AUTOSAR XML (schema 4-0-3)
standard types defined: Boolean, UInt16
package /AUTOSAR_Platform/DataConstrs
  range DC_Boolean: raw 0..1
  range DC_UInt16: raw 0..65535
package /PATAC/MSM/ComponentTypes
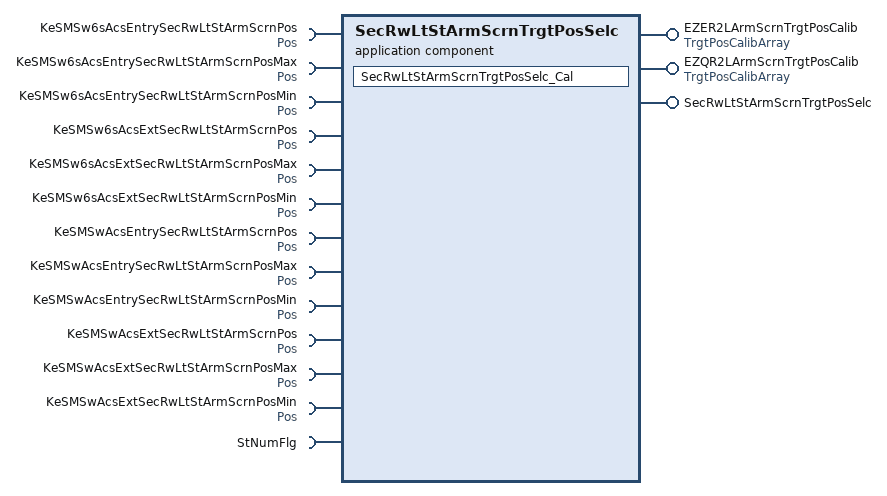
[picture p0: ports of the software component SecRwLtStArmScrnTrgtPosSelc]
  application sw component type SecRwLtStArmScrnTrgtPosSelc
    provide port EZER2LArmScrnTrgtPosCalib: nonqueued-sender-com-spec{data-element=TrgtPosArray, init-value=[4095, 4095, 4095]}, provided-interface=TrgtPosCalibArray
    provide port EZQR2LArmScrnTrgtPosCalib: nonqueued-sender-com-spec{data-element=TrgtPosArray, init-value=[4095, 4095, 4095]}, provided-interface=TrgtPosCalibArray
    provide port SecRwLtStArmScrnTrgtPosSelc: server-com-spec{operation=Cal, queue-length=1}, provided-interface=SecRwLtStArmScrnTrgtPosSelc
    13 x require port:
      KeSMSw6sAcsEntrySecRwLtStArmScrnPos: parameter-require-com-spec{init-value=0, parameter=Val}, required-interface=Pos
      KeSMSw6sAcsEntrySecRwLtStArmScrnPosMax: parameter-require-com-spec{init-value=0, parameter=Val}, required-interface=Pos
      KeSMSw6sAcsEntrySecRwLtStArmScrnPosMin: parameter-require-com-spec{init-value=0, parameter=Val}, required-interface=Pos
      KeSMSw6sAcsExtSecRwLtStArmScrnPos: parameter-require-com-spec{init-value=30, parameter=Val}, required-interface=Pos
      KeSMSw6sAcsExtSecRwLtStArmScrnPosMax: parameter-require-com-spec{init-value=40, parameter=Val}, required-interface=Pos
      KeSMSw6sAcsExtSecRwLtStArmScrnPosMin: parameter-require-com-spec{init-value=20, parameter=Val}, required-interface=Pos
      KeSMSwAcsEntrySecRwLtStArmScrnPos: parameter-require-com-spec{init-value=0, parameter=Val}, required-interface=Pos
      KeSMSwAcsEntrySecRwLtStArmScrnPosMax: parameter-require-com-spec{init-value=0, parameter=Val}, required-interface=Pos
      KeSMSwAcsEntrySecRwLtStArmScrnPosMin: parameter-require-com-spec{init-value=0, parameter=Val}, required-interface=Pos
      KeSMSwAcsExtSecRwLtStArmScrnPos: parameter-require-com-spec{init-value=30, parameter=Val}, required-interface=Pos
      KeSMSwAcsExtSecRwLtStArmScrnPosMax: parameter-require-com-spec{init-value=40, parameter=Val}, required-interface=Pos
      KeSMSwAcsExtSecRwLtStArmScrnPosMin: parameter-require-com-spec{init-value=20, parameter=Val}, required-interface=Pos
      StNumFlg: required-interface=StNumFlg
        required-com-specs:
          data-element=Is4s, filter=data-filter-type=ALWAYS, init-value=0
          data-element=Is6s, filter=data-filter-type=ALWAYS, init-value=0
          data-element=Is6s7s, filter=data-filter-type=ALWAYS, init-value=0
          data-element=Is7s, filter=data-filter-type=ALWAYS, init-value=0
    behavior SecRwLtStArmScrnTrgtPosSelc_InternalBehavior
      operation invoked event OIT_SecRwLtStArmScrnTrgtPosSelc_Cal_SecRwLtStArmScrnTrgtPosSelc_Cal: start-on-event=SecRwLtStArmScrnTrgtPosSelc_Cal, operation=SecRwLtStArmScrnTrgtPosSelc.Cal
      runnable SecRwLtStArmScrnTrgtPosSelc_Cal
        data-receive-point-by-arguments:
          4 x access:
            REC_StNumFlg_Is4s: accessed-variable=StNumFlg.Is4s
            REC_StNumFlg_Is6s: accessed-variable=StNumFlg.Is6s
            REC_StNumFlg_Is6s7s: accessed-variable=StNumFlg.Is6s7s
            REC_StNumFlg_Is7s: accessed-variable=StNumFlg.Is7s
        data-send-points:
          access SEND_EZER2LArmScrnTrgtPosCalib_TrgtPosArray: accessed-variable=EZER2LArmScrnTrgtPosCalib.TrgtPosArray
          access SEND_EZQR2LArmScrnTrgtPosCalib_TrgtPosArray: accessed-variable=EZQR2LArmScrnTrgtPosCalib.TrgtPosArray
        12 x parameter access:
          PA_KeSMSw6sAcsEntrySecRwLtStArmScrnPos_Val: accessed-parameter=KeSMSw6sAcsEntrySecRwLtStArmScrnPos.Val
          PA_KeSMSw6sAcsEntrySecRwLtStArmScrnPosMax_Val: accessed-parameter=KeSMSw6sAcsEntrySecRwLtStArmScrnPosMax.Val
          PA_KeSMSw6sAcsEntrySecRwLtStArmScrnPosMin_Val: accessed-parameter=KeSMSw6sAcsEntrySecRwLtStArmScrnPosMin.Val
          PA_KeSMSw6sAcsExtSecRwLtStArmScrnPos_Val: accessed-parameter=KeSMSw6sAcsExtSecRwLtStArmScrnPos.Val
          PA_KeSMSw6sAcsExtSecRwLtStArmScrnPosMax_Val: accessed-parameter=KeSMSw6sAcsExtSecRwLtStArmScrnPosMax.Val
          PA_KeSMSw6sAcsExtSecRwLtStArmScrnPosMin_Val: accessed-parameter=KeSMSw6sAcsExtSecRwLtStArmScrnPosMin.Val
          PA_KeSMSwAcsEntrySecRwLtStArmScrnPos_Val: accessed-parameter=KeSMSwAcsEntrySecRwLtStArmScrnPos.Val
          PA_KeSMSwAcsEntrySecRwLtStArmScrnPosMax_Val: accessed-parameter=KeSMSwAcsEntrySecRwLtStArmScrnPosMax.Val
          PA_KeSMSwAcsEntrySecRwLtStArmScrnPosMin_Val: accessed-parameter=KeSMSwAcsEntrySecRwLtStArmScrnPosMin.Val
          PA_KeSMSwAcsExtSecRwLtStArmScrnPos_Val: accessed-parameter=KeSMSwAcsExtSecRwLtStArmScrnPos.Val
          PA_KeSMSwAcsExtSecRwLtStArmScrnPosMax_Val: accessed-parameter=KeSMSwAcsExtSecRwLtStArmScrnPosMax.Val
          PA_KeSMSwAcsExtSecRwLtStArmScrnPosMin_Val: accessed-parameter=KeSMSwAcsExtSecRwLtStArmScrnPosMin.Val
  swc implementation SecRwLtStArmScrnTrgtPosSelc_Implementation: behavior=SecRwLtStArmScrnTrgtPosSelc_InternalBehavior
    code-descriptors:
      code Default: artifact-descriptors=autosar-engineering-object={short-label=Default, category=SWSRC}
package /PATAC/MSM/ModeAdjust/CalPortInterface
  parameter interface Pos
    parameter data prototype Val: sw-calibration-access=READ-WRITE, type=UInt16
package /PATAC/MSM/ModeAdjust/DataType
  impl type TrgtPosCalibArray: category=ARRAY, sw-calibration-access=READ-ONLY, type-emitter=RTE  # 0:pos 1:max 2:min
    element Element: array-size=3, array-size-semantics=FIXED-SIZE, implementation-data-type=UInt16, invalid-value=0
package /PATAC/MSM/ModeAdjust/PortInterface
  client server interface SecRwLtStArmScrnTrgtPosSelc
    operation Cal
  sender receiver interface StNumFlg
    4 x data, all with type=Boolean:
      Is4s
      Is6s
      Is6s7s
      Is7s
    invalidation-policys:
      data-element=Is7s, handle-invalid=DONT-INVALIDATE
      data-element=Is6s, handle-invalid=DONT-INVALIDATE
      data-element=Is4s, handle-invalid=DONT-INVALIDATE
      data-element=Is6s7s, handle-invalid=DONT-INVALIDATE
  sender receiver interface TrgtPosCalibArray: invalidation-policy{data-element=TrgtPosArray, handle-invalid=DONT-INVALIDATE}
    data TrgtPosArray: type=TrgtPosCalibArray  # 0:Pos 1:Max 2:Min
